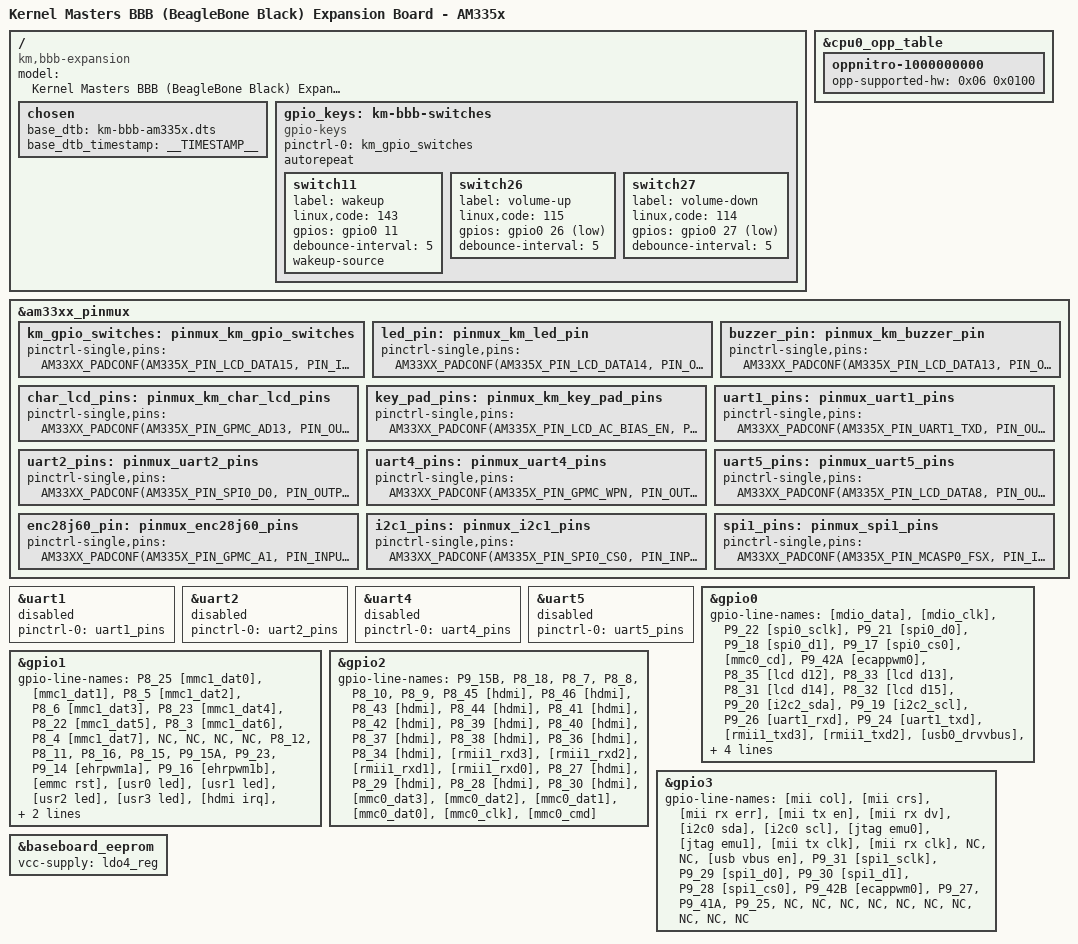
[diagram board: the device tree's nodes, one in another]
// SPDX-License-Identifier: GPL-2.0-only
/*
 * Copyright (C) 2012 Texas Instruments Incorporated - https://www.ti.com/
 */
/dts-v1/;

#include "am33xx.dtsi"
#include "am335x-bone-common.dtsi"
#include "am335x-boneblack-common.dtsi"
#include "am335x-boneblack-hdmi.dtsi"

/ {
	model = "Kernel Masters BBB (BeagleBone Black) Expansion Board - AM335x";
	compatible = "km,bbb-expansion", "ti,am335x-bone-black", "ti,am335x-bone", "ti,am33xx";

	chosen {
		base_dtb = "km-bbb-am335x.dts";
		base_dtb_timestamp = __TIMESTAMP__;
	};

	gpio_keys: km-bbb-switches {
		compatible = "gpio-keys";
		pinctrl-names = "default";
		pinctrl-0 = <&km_gpio_switches>;
		autorepeat;

	        switch11 {
			label = "wakeup";
			linux,code = <143>;
			/*linux,code = <KEY_WAKEUP>;*/
			gpios = <&gpio0 11 GPIO_ACTIVE_HIGH>;
			debounce-interval = <5>;
			wakeup-source;
                };

		switch26 {
			label = "volume-up";
			linux,code = <115>;
			/*linux,code = <KEY_VOLUMEUP>;*/
			gpios = <&gpio0 26 GPIO_ACTIVE_LOW>;
			debounce-interval = <5>;
                };

                switch27 {
			label = "volume-down";
			linux,code = <114>;
			/*linux,code = <KEY_VOLUMEDOWN>;*/
			gpios = <&gpio0 27 GPIO_ACTIVE_LOW>;
			debounce-interval = <5>;
		};
	};
};

&cpu0_opp_table {
	/*
	 * All PG 2.0 silicon may not support 1GHz but some of the early
	 * BeagleBone Blacks have PG 2.0 silicon which is guaranteed
	 * to support 1GHz OPP so enable it for PG 2.0 on this board.
	 */
	oppnitro-1000000000 {
		opp-supported-hw = <0x06 0x0100>;
	};
};

/* For modifing this you need to refer BBB P8 & P9 HeaderTable.pdf */
&am33xx_pinmux {
	km_gpio_switches: pinmux_km_gpio_switches {
                pinctrl-single,pins = <
                        AM33XX_PADCONF(AM335X_PIN_LCD_DATA15, PIN_INPUT_PULLDOWN, MUX_MODE7)   /* P8_32 (GPIO0_11) USER_SW */
                        AM33XX_PADCONF(AM335X_PIN_GPMC_AD10, PIN_INPUT_PULLUP, MUX_MODE7)      /* P8_14 (GPIO0_26) SW_UP */
                        AM33XX_PADCONF(AM335X_PIN_GPMC_AD11, PIN_INPUT_PULLUP, MUX_MODE7)      /* P8_17 (GPIO0_27) SW_DOWN */
                >;
	};

	led_pin: pinmux_km_led_pin {
		pinctrl-single,pins = <
			AM33XX_PADCONF(AM335X_PIN_LCD_DATA14, PIN_OUTPUT_PULLDOWN, MUX_MODE7)   /* P8_31 (GPIO0_10) USER_LED */
		>;
	};

	buzzer_pin: pinmux_km_buzzer_pin {
		pinctrl-single,pins = <
			AM33XX_PADCONF(AM335X_PIN_LCD_DATA13, PIN_OUTPUT, MUX_MODE7)   /* P8_33 (GPIO0_9) BUZZER */
		>;
	};

	char_lcd_pins: pinmux_km_char_lcd_pins {
		pinctrl-single,pins = <
			AM33XX_PADCONF(AM335X_PIN_GPMC_AD13, PIN_OUTPUT, MUX_MODE7)   /* P8_11 (GPIO1_13) LCD_D5 */
			AM33XX_PADCONF(AM335X_PIN_GPMC_AD12, PIN_OUTPUT, MUX_MODE7)   /* P8_12 (GPIO1_12) LCD_D4 */
			AM33XX_PADCONF(AM335X_PIN_GPMC_AD15, PIN_OUTPUT, MUX_MODE7)   /* P8_15 (GPIO1_15) LCD_D7 */
			AM33XX_PADCONF(AM335X_PIN_GPMC_AD14, PIN_OUTPUT, MUX_MODE7)   /* P8_16 (GPIO1_14) LCD_D6 */
			AM33XX_PADCONF(AM335X_PIN_LCD_VSYNC, PIN_OUTPUT, MUX_MODE7)   /* P8_27 (GPIO2_22) LCD_RS */
			AM33XX_PADCONF(AM335X_PIN_LCD_PCLK,  PIN_OUTPUT, MUX_MODE7)   /* P8_28 (GPIO2_24) LCD_EN */
			AM33XX_PADCONF(AM335X_PIN_LCD_HSYNC, PIN_OUTPUT, MUX_MODE7)   /* P8_29 (GPIO2_23) LCD_RW */
		>;
	};

	key_pad_pins: pinmux_km_key_pad_pins {
		pinctrl-single,pins = <
			AM33XX_PADCONF(AM335X_PIN_LCD_AC_BIAS_EN, PIN_INPUT_PULLDOWN, MUX_MODE7)	/* P8_30 (GPIO2_25) KEY_PAD_8 */
			AM33XX_PADCONF(AM335X_PIN_LCD_DATA6, PIN_INPUT, MUX_MODE7)   			/* P8_39 (GPIO2_12) KEY_PAD_6 */
			AM33XX_PADCONF(AM335X_PIN_LCD_DATA7, PIN_INPUT, MUX_MODE7)   			/* P8_40 (GPIO2_13) KEY_PAD_7 */
			AM33XX_PADCONF(AM335X_PIN_LCD_DATA4, PIN_INPUT, MUX_MODE7)   			/* P8_41 (GPIO2_10) KEY_PAD_4 */
			AM33XX_PADCONF(AM335X_PIN_LCD_DATA5, PIN_INPUT, MUX_MODE7)   			/* P8_42 (GPIO2_11) KEY_PAD_5 */
			AM33XX_PADCONF(AM335X_PIN_LCD_DATA2, PIN_INPUT, MUX_MODE7)   			/* P8_43 (GPIO2_8)  KEY_PAD_2 */
			AM33XX_PADCONF(AM335X_PIN_LCD_DATA3, PIN_INPUT, MUX_MODE7)   			/* P8_44 (GPIO2_9)  KEY_PAD_3 */
			AM33XX_PADCONF(AM335X_PIN_LCD_DATA0, PIN_INPUT, MUX_MODE7)   			/* P8_45 (GPIO2_6)  KEY_PAD_0 */
			AM33XX_PADCONF(AM335X_PIN_LCD_DATA1, PIN_INPUT, MUX_MODE7)   			/* P8_46 (GPIO2_7)  KEY_PAD_1 */
		>;
	};

	uart1_pins: pinmux_uart1_pins {
		pinctrl-single,pins = <
			AM33XX_PADCONF(AM335X_PIN_UART1_TXD, PIN_OUTPUT_PULLDOWN, MUX_MODE0)	/* P9_24 UART1_TXD */
			AM33XX_PADCONF(AM335X_PIN_UART1_RXD, PIN_INPUT_PULLUP, MUX_MODE0)	/* P9_26 UART1_RXD */
                >;
	};

	uart2_pins: pinmux_uart2_pins {
		pinctrl-single,pins = <
			AM33XX_PADCONF(AM335X_PIN_SPI0_D0, PIN_OUTPUT_PULLDOWN, MUX_MODE1)	/* P9_21 UART2_TXD */
			AM33XX_PADCONF(AM335X_PIN_SPI0_SCLK, PIN_INPUT_PULLUP, MUX_MODE1)	/* P9_22 UART2_RXD */
                >;
	};

	uart4_pins:pinmux_uart4_pins {
		pinctrl-single,pins = <
			AM33XX_PADCONF(AM335X_PIN_GPMC_WPN, PIN_OUTPUT_PULLDOWN, MUX_MODE6)	/* P9_13 UART4_TXD */
			AM33XX_PADCONF(AM335X_PIN_GPMC_WAIT0, PIN_INPUT_PULLUP, MUX_MODE6)	/* P9_11 UART4_RXD */
			/* this is additional for RS485 - is this required?? */
			/* 0x078   0x0f */   /*P9_12(GPIO1_28-->RS485_CONTROL)Mode7|Pull_UPDN Disable*/
		>;
	};

	uart5_pins: pinmux_uart5_pins {
		pinctrl-single,pins = <
			AM33XX_PADCONF(AM335X_PIN_LCD_DATA8, PIN_OUTPUT_PULLDOWN, MUX_MODE4)	/* P8_37 UART5_TXD */
			AM33XX_PADCONF(AM335X_PIN_LCD_DATA9, PIN_INPUT_PULLUP, MUX_MODE4)	/* P8_38 UART5_RXD */
		>;
	};

	enc28j60_pin: pinmux_enc28j60_pins {
		pinctrl-single,pins = <
			AM33XX_PADCONF(AM335X_PIN_GPMC_A1, PIN_INPUT_PULLUP, MUX_MODE7)   /* P9_23 (GPIO1_17) ENC28J60_INT */
		>;
	};

	i2c1_pins:pinmux_i2c1_pins {
		pinctrl-single,pins = <
			AM33XX_PADCONF(AM335X_PIN_SPI0_CS0, PIN_INPUT_PULLUP, MUX_MODE2)        /* P9_17 I2C1_SCL */
			AM33XX_PADCONF(AM335X_PIN_SPI0_D1, PIN_INPUT_PULLUP, MUX_MODE2)		/* P9_18 I2C1_SDA */
		>;
	};

	spi1_pins:pinmux_spi1_pins {
		pinctrl-single,pins = <
			AM33XX_PADCONF(AM335X_PIN_MCASP0_FSX, PIN_INPUT_PULLUP, MUX_MODE3)	/* P9_29 SPI1_MISO */
			AM33XX_PADCONF(AM335X_PIN_MCASP0_AXR0, PIN_OUTPUT_PULLUP, MUX_MODE3)	/* P9_30 SPI1_MOSI */
			AM33XX_PADCONF(AM335X_PIN_MCASP0_ACLKX, PIN_INPUT_PULLUP, MUX_MODE3)    /* P9_31 SPI1_SCLK */
			AM33XX_PADCONF(AM335X_PIN_MCASP0_AHCLKR, PIN_OUTPUT_PULLUP, MUX_MODE3)	/* P9_28 SPI1_CS0 */
		>;
	};
};

&uart1 {
        pinctrl-names = "default";
        pinctrl-0 = <&uart1_pins>;

	status = "disabled";
};

&uart2 {
        pinctrl-names = "default";
        pinctrl-0 = <&uart2_pins>;

        status = "disabled";
};

&uart4 {
        pinctrl-names = "default";
        pinctrl-0 = <&uart4_pins>;

        status = "disabled";

/* this is additional for RS485 - is this required?? */
/*
        rts-gpio = <&gpio1 28 GPIO_ACTIVE_HIGH>;
        rs485-rts-active-high;
        rs485-rx-during-tx;
        rs485-rts-delay = <1 1>;
        linux,rs485-enabled-at-boot-time;
*/
};

&uart5 {
        pinctrl-names = "default";
        pinctrl-0 = <&uart5_pins>;

	status = "disabled";
};





/*
 * The below gpiolibd support information comes from am335x-boneblack.dts, used
 * as a base in the creation of km-bbb-am335x.dts.
 */
&gpio0 {
	gpio-line-names =
		"[mdio_data]",
		"[mdio_clk]",
		"P9_22 [spi0_sclk]",
		"P9_21 [spi0_d0]",
		"P9_18 [spi0_d1]",
		"P9_17 [spi0_cs0]",
		"[mmc0_cd]",
		"P9_42A [ecappwm0]",
		"P8_35 [lcd d12]",
		"P8_33 [lcd d13]",
		"P8_31 [lcd d14]",
		"P8_32 [lcd d15]",
		"P9_20 [i2c2_sda]",
		"P9_19 [i2c2_scl]",
		"P9_26 [uart1_rxd]",
		"P9_24 [uart1_txd]",
		"[rmii1_txd3]",
		"[rmii1_txd2]",
		"[usb0_drvvbus]",
		"[hdmi cec]",
		"P9_41B",
		"[rmii1_txd1]",
		"P8_19 [ehrpwm2a]",
		"P8_13 [ehrpwm2b]",
		"NC",
		"NC",
		"P8_14",
		"P8_17",
		"[rmii1_txd0]",
		"[rmii1_refclk]",
		"P9_11 [uart4_rxd]",
		"P9_13 [uart4_txd]";
};

&gpio1 {
	gpio-line-names =
		"P8_25 [mmc1_dat0]",
		"[mmc1_dat1]",
		"P8_5 [mmc1_dat2]",
		"P8_6 [mmc1_dat3]",
		"P8_23 [mmc1_dat4]",
		"P8_22 [mmc1_dat5]",
		"P8_3 [mmc1_dat6]",
		"P8_4 [mmc1_dat7]",
		"NC",
		"NC",
		"NC",
		"NC",
		"P8_12",
		"P8_11",
		"P8_16",
		"P8_15",
		"P9_15A",
		"P9_23",
		"P9_14 [ehrpwm1a]",
		"P9_16 [ehrpwm1b]",
		"[emmc rst]",
		"[usr0 led]",
		"[usr1 led]",
		"[usr2 led]",
		"[usr3 led]",
		"[hdmi irq]",
		"[usb vbus oc]",
		"[hdmi audio]",
		"P9_12",
		"P8_26",
		"P8_21 [emmc]",
		"P8_20 [emmc]";
};

&gpio2 {
	gpio-line-names =
		"P9_15B",
		"P8_18",
		"P8_7",
		"P8_8",
		"P8_10",
		"P8_9",
		"P8_45 [hdmi]",
		"P8_46 [hdmi]",
		"P8_43 [hdmi]",
		"P8_44 [hdmi]",
		"P8_41 [hdmi]",
		"P8_42 [hdmi]",
		"P8_39 [hdmi]",
		"P8_40 [hdmi]",
		"P8_37 [hdmi]",
		"P8_38 [hdmi]",
		"P8_36 [hdmi]",
		"P8_34 [hdmi]",
		"[rmii1_rxd3]",
		"[rmii1_rxd2]",
		"[rmii1_rxd1]",
		"[rmii1_rxd0]",
		"P8_27 [hdmi]",
		"P8_29 [hdmi]",
		"P8_28 [hdmi]",
		"P8_30 [hdmi]",
		"[mmc0_dat3]",
		"[mmc0_dat2]",
		"[mmc0_dat1]",
		"[mmc0_dat0]",
		"[mmc0_clk]",
		"[mmc0_cmd]";
};

&gpio3 {
	gpio-line-names =
		"[mii col]",
		"[mii crs]",
		"[mii rx err]",
		"[mii tx en]",
		"[mii rx dv]",
		"[i2c0 sda]",
		"[i2c0 scl]",
		"[jtag emu0]",
		"[jtag emu1]",
		"[mii tx clk]",
		"[mii rx clk]",
		"NC",
		"NC",
		"[usb vbus en]",
		"P9_31 [spi1_sclk]",
		"P9_29 [spi1_d0]",
		"P9_30 [spi1_d1]",
		"P9_28 [spi1_cs0]",
		"P9_42B [ecappwm0]",
		"P9_27",
		"P9_41A",
		"P9_25",
		"NC",
		"NC",
		"NC",
		"NC",
		"NC",
		"NC",
		"NC",
		"NC",
		"NC",
		"NC";
};

&baseboard_eeprom {
	vcc-supply = <&ldo4_reg>;
};
